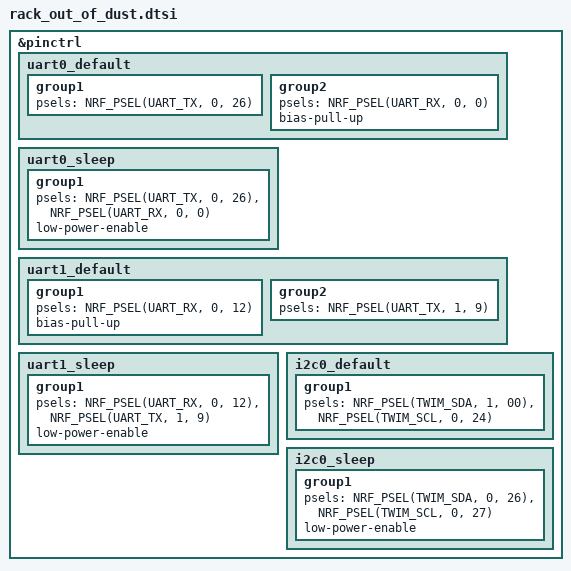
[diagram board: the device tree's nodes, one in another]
/*
 * Copyright (c) 2022 Nordic Semiconductor
 * SPDX-License-Identifier: Apache-2.0
 */

&pinctrl {
  uart0_default: uart0_default {
    group1 {
      psels = <NRF_PSEL(UART_TX, 0, 26)>;
    };
    group2 {
      psels = <NRF_PSEL(UART_RX, 0, 0)>;
      bias-pull-up;
    };
  };

  uart0_sleep: uart0_sleep {
    group1 {
      psels = <NRF_PSEL(UART_TX, 0, 26)>,
              <NRF_PSEL(UART_RX, 0, 0)>;
      low-power-enable;
    };
  };

  uart1_default: uart1_default {
    group1 {
      psels = <NRF_PSEL(UART_RX, 0, 12)>;
      bias-pull-up;
    };
    group2 {
      psels = <NRF_PSEL(UART_TX, 1, 9)>;
    };
  };

  uart1_sleep: uart1_sleep {
    group1 {
      psels = <NRF_PSEL(UART_RX, 0, 12)>,
              <NRF_PSEL(UART_TX, 1, 9)>;
      low-power-enable;
    };
  };

  i2c0_default: i2c0_default {
    group1 {
      psels = <NRF_PSEL(TWIM_SDA, 1, 00)>,
              <NRF_PSEL(TWIM_SCL, 0, 24)>;
    };
  };

  i2c0_sleep: i2c0_sleep {
    group1 {
      psels = <NRF_PSEL(TWIM_SDA, 0, 26)>,
              <NRF_PSEL(TWIM_SCL, 0, 27)>;
      low-power-enable;
    };
  };
};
